# MDR1986BE3T register map
Vendor: Milandr; File version: 1.0
CPU: CM1 r0p0, little endian, no MPU, no FPU, 3 interrupt priority bits
Registers are 32-bit, read-write, reset 0x0 unless marked. A register's access mark holds for its fields unless they carry their own. Offsets are from the block's base; [hi:lo] are bit positions; 'fields as' and 'values as' point back to an identical list.

## MDR_DMA — DMA controller registers
Base 0x40028000; register names take the prefix MDR_DMA_
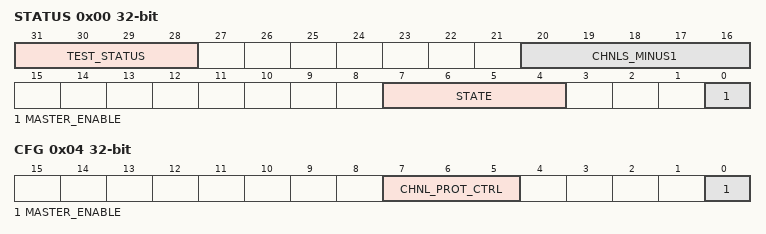
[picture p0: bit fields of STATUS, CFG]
0x00 STATUS — DMA Status Register
  [31:28] TEST_STATUS, [20:16] CHNLS_MINUS1, [7:4] STATE, [0] MASTER_ENABLE
0x04 CFG — DMA Configuration Register
  [7:5] CHNL_PROT_CTRL, [0] MASTER_ENABLE
0x08 CTRL_BASE_PTR
0x0C ALT_CTRL_BASE_PTR
0x10 WAITONREQ_STATUS
0x14 CHNL_SW_REQUEST
0x18 CHNL_USEBURST_SET
0x1C CHNL_USEBURST_CLR
0x20 CHNL_REQ_MASK_SET
0x24 CHNL_REQ_MASK_CLR
0x28 CHNL_ENABLE_SET
0x2C CHNL_ENABLE_CLR
0x30 CHNL_PRI_ALT_SET
0x34 CHNL_PRI_ALT_CLR
0x38 CHNL_PRIORITY_SET
0x3C CHNL_PRIORITY_CLR
0x4C ERR_CLR
  [0] ERR_CLR

## MDR_UART1 — UART1 interfase controller registers
Base 0x40030000; register names take the prefix MDR_UART1_
Same registers: MDR_UART2 0x40038000 (register names take the prefix MDR_UART2_), MDR_UART3 0x40120000 (register names take the prefix MDR_UART3_), MDR_UART4 0x40128000 (register names take the prefix MDR_UART4_)
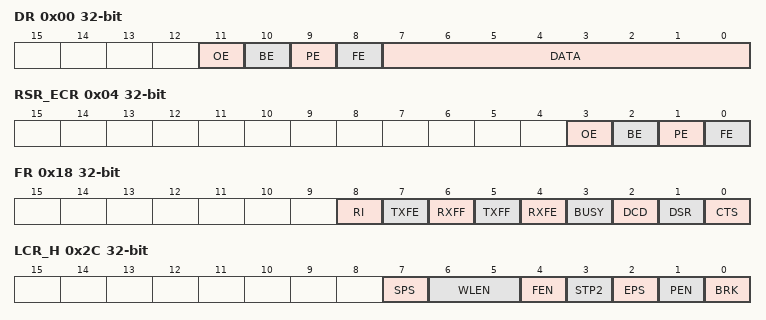
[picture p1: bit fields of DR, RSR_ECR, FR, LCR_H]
0x00 DR — UART Data Register
  [11] OE, [10] BE, [9] PE, [8] FE, [7:0] DATA
0x04 RSR_ECR — UART RSR Register
  [3] OE, [2] BE, [1] PE, [0] FE
0x18 FR — UART Flag Register
  [8] RI, [7] TXFE, [6] RXFF, [5] TXFF, [4] RXFE, [3] BUSY, [2] DCD, [1] DSR, [0] CTS
0x20 ILPR
  [7:0] ILPDVSR
0x24 IBRD
  [15:0] BAUD_DIVINT
0x28 FBRD
  [5:0] BAUD_DIVFRAC
0x2C LCR_H — UART LCR_H Register
  [7] SPS, [6:5] WLEN, [4] FEN, [3] STP2, [2] EPS, [1] PEN, [0] BRK
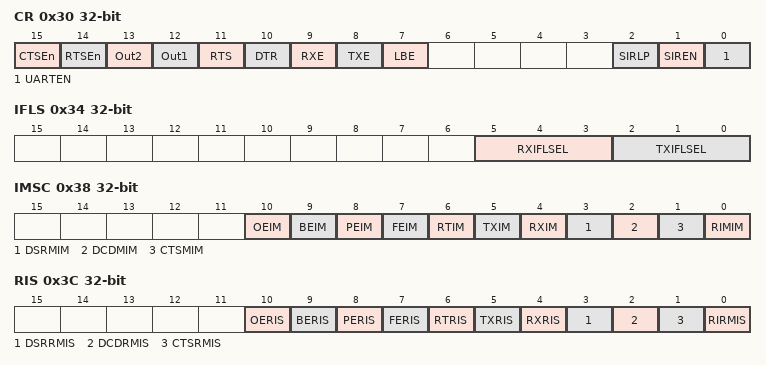
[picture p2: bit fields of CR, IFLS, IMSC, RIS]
0x30 CR — UART Command Register
  [15] CTSEn, [14] RTSEn, [13] Out2, [12] Out1, [11] RTS, [10] DTR, [9] RXE, [8] TXE, [7] LBE, [2] SIRLP, [1] SIREN, [0] UARTEN
0x34 IFLS — UART IFLS Register
  [5:3] RXIFLSEL, [2:0] TXIFLSEL
0x38 IMSC — UART Interrupt Mask Register
  [10] OEIM, [9] BEIM, [8] PEIM, [7] FEIM, [6] RTIM, [5] TXIM, [4] RXIM, [3] DSRMIM, [2] DCDMIM, [1] CTSMIM, [0] RIMIM
0x3C RIS — UART Interrupt Pending Register
  [10] OERIS, [9] BERIS, [8] PERIS, [7] FERIS, [6] RTRIS, [5] TXRIS, [4] RXRIS, [3] DSRRMIS, [2] DCDRMIS, [1] CTSRMIS, [0] RIRMIS
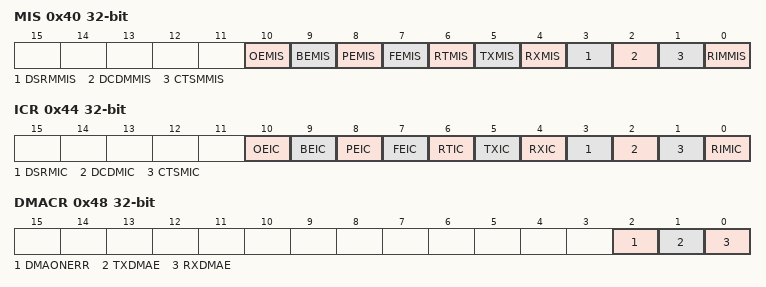
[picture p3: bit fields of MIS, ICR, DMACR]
0x40 MIS — UART Masked Interrupt Pending Register
  [10] OEMIS, [9] BEMIS, [8] PEMIS, [7] FEMIS, [6] RTMIS, [5] TXMIS, [4] RXMIS, [3] DSRMMIS, [2] DCDMMIS, [1] CTSMMIS, [0] RIMMIS
0x44 ICR — UART Interrupt Clear Register
  [10] OEIC, [9] BEIC, [8] PEIC, [7] FEIC, [6] RTIC, [5] TXIC, [4] RXIC, [3] DSRMIC, [2] DCDMIC, [1] CTSMIC, [0] RIMIC
0x48 DMACR — UART DMA Control Register
  [2] DMAONERR, [1] TXDMAE, [0] RXDMAE

## MDR_SSP1 — SSP1 interfase controller registers
Base 0x40040000; register names take the prefix MDR_SSP1_
Same registers: MDR_SSP2 0x400A0000 (register names take the prefix MDR_SSP2_), MDR_SSP3 0x400F8000 (register names take the prefix MDR_SSP3_), MDR_SSP4 0x40130000 (register names take the prefix MDR_SSP4_)
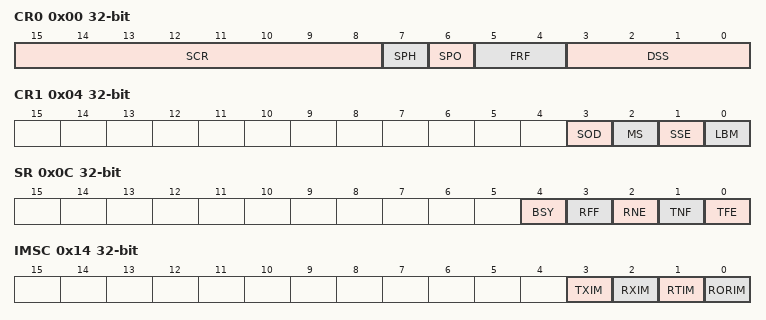
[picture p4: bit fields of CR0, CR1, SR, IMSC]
0x00 CR0 — SSP Control0 Register
  [15:8] SCR, [7] SPH, [6] SPO, [5:4] FRF, [3:0] DSS
0x04 CR1 — SSP Control1 Register
  [3] SOD, [2] MS, [1] SSE, [0] LBM
0x08 DR — SSP Data Register
  [15:0] DATA
0x0C SR — SSP Status Register
  [4] BSY, [3] RFF, [2] RNE, [1] TNF, [0] TFE
0x10 CPSR — SSP Clock Prescaler Register
  [7:0] CPSDVSR
0x14 IMSC — SSP Interrupt Mask Register
  [3] TXIM, [2] RXIM, [1] RTIM, [0] RORIM
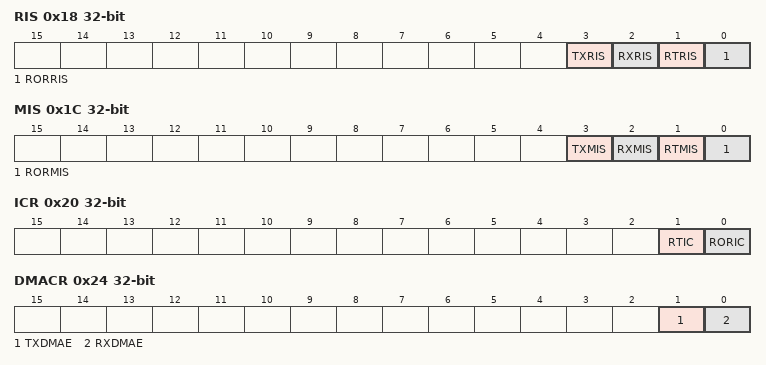
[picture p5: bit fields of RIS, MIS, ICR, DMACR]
0x18 RIS — SSP Interrupt Pending Register
  [3] TXRIS, [2] RXRIS, [1] RTRIS, [0] RORRIS
0x1C MIS — SSP Masked Interrupt Pending Register
  [3] TXMIS, [2] RXMIS, [1] RTMIS, [0] RORMIS
0x20 ICR — SSP Interrupt Clear Register
  [1] RTIC, [0] RORIC
0x24 DMACR — SSP DMA Control Register
  [1] TXDMAE, [0] RXDMAE

## MDR_MILSTD1 — MIL_STD_1553 interfase controller registers
Base 0x40048000; register names take the prefix MDR_MILSTD1_
Same registers: MDR_MILSTD2 0x40050000 (register names take the prefix MDR_MILSTD2_)
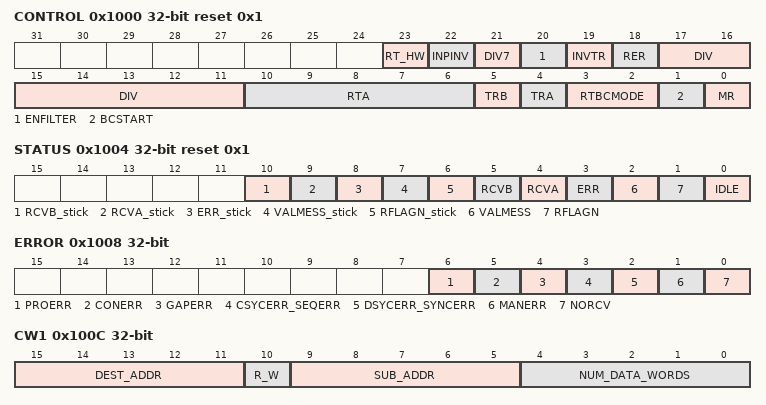
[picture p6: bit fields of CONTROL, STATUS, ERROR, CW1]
0x1000 CONTROL reset 0x1 — MIL_STD_1553 Register control
  [23] RT_HW, [22] INPINV, [21] DIV7, [20] ENFILTER, [19] INVTR, [18] RER, [17:11] DIV, [10:6] RTA, [5] TRB, [4] TRA, [3:2] RTBCMODE, [1] BCSTART, [0] MR
0x1004 STATUS reset 0x1 (reset mask 0x7F) — MIL_STD_1553 Register status
  [10] RCVB_stick, [9] RCVA_stick, [8] ERR_stick, [7] VALMESS_stick, [6] RFLAGN_stick, [5] RCVB ro, [4] RCVA ro, [3] ERR ro, [2] VALMESS ro, [1] RFLAGN ro, [0] IDLE ro
0x1008 ERROR ro — MILSTD Register error
  [6] PROERR, [5] CONERR, [4] GAPERR, [3] CSYCERR_SEQERR, [2] DSYCERR_SYNCERR, [1] MANERR, [0] NORCV
0x100C CW1 — MILSTD Register Command Word 1
  [15:11] DEST_ADDR, [10] R_W, [9:5] SUB_ADDR, [4:0] NUM_DATA_WORDS
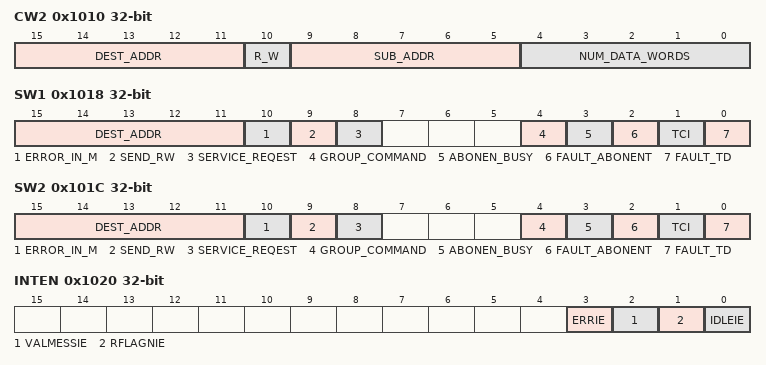
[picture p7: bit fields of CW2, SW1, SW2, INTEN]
0x1010 CW2 — MILSTD Register Command Word 2
  [15:11] DEST_ADDR, [10] R_W, [9:5] SUB_ADDR, [4:0] NUM_DATA_WORDS
0x1014 MODE_DATA — MILSTD Register Data
  [15:0] MODE_DATA
0x1018 SW1 — MILSTD Register Status Word 1
  [15:11] DEST_ADDR, [10] ERROR_IN_M, [9] SEND_RW, [8] SERVICE_REQEST, [4] GROUP_COMMAND, [3] ABONEN_BUSY, [2] FAULT_ABONENT, [1] TCI, [0] FAULT_TD
0x101C SW2 — MILSTD Register Status Word 2
  fields as SW1
0x1020 INTEN — MILSTD
  [3] ERRIE, [2] VALMESSIE, [1] RFLAGNIE, [0] IDLEIE
0x1024 MSG ro — MILSTD
  [13:0] MESSAGE_CODE
